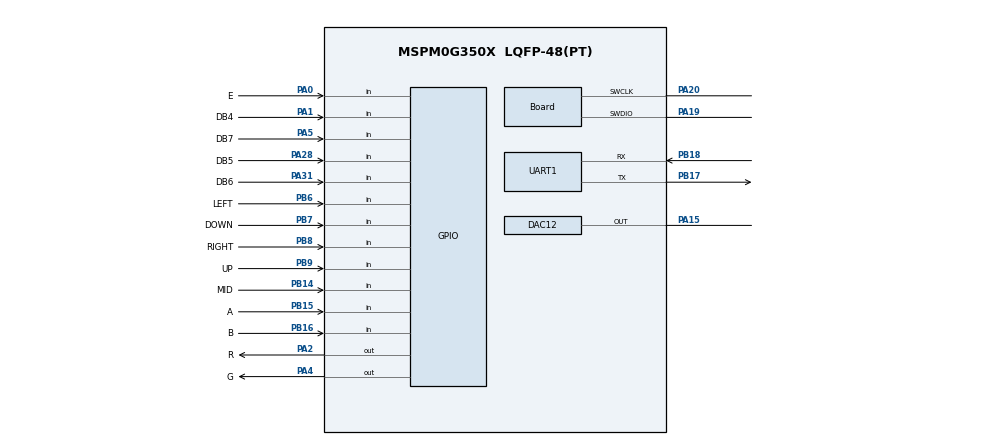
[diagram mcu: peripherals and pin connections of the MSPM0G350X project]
/**
 * @cliArgs --device "MSPM0G350X" --part "Default" --package "LQFP-48(PT)" --product "mspm0_sdk@2.04.00.06"
 * @versions {"tool":"1.23.1+4034"}
 */

/**
 * Import the modules used in this configuration.
 */
const ADC12   = scripting.addModule("/ti/driverlib/ADC12", {}, false);
const ADC121  = ADC12.addInstance();
const DAC12   = scripting.addModule("/ti/driverlib/DAC12");
const GPIO    = scripting.addModule("/ti/driverlib/GPIO", {}, false);
const GPIO1   = GPIO.addInstance();
const GPIO2   = GPIO.addInstance();
const GPIO3   = GPIO.addInstance();
const GPIO4   = GPIO.addInstance();
const SYSCTL  = scripting.addModule("/ti/driverlib/SYSCTL");
const SYSTICK = scripting.addModule("/ti/driverlib/SYSTICK");
const UART    = scripting.addModule("/ti/driverlib/UART", {}, false);
const UART1   = UART.addInstance();
const UART2   = UART.addInstance();

/**
 * Write custom configuration values to the imported modules.
 */
const gate8  = system.clockTree["MFPCLKGATE"];
gate8.enable = true;

const pinFunction3     = system.clockTree["HFCLKEXT"];
pinFunction3.inputFreq = 40;

ADC121.$name                 = "ADC12_0";
ADC121.sampClkDiv            = "DL_ADC12_CLOCK_DIVIDE_8";
ADC121.samplingOperationMode = "sequence";
ADC121.endAdd                = 1;
ADC121.enabledInterrupts     = ["DL_ADC12_INTERRUPT_MEM1_RESULT_LOADED"];
ADC121.interruptPriority     = "3";
ADC121.sampleTime0           = "40 us";
ADC121.adcPin0Config.$name   = "ti_driverlib_gpio_GPIOPinGeneric3";

const Board                       = scripting.addModule("/ti/driverlib/Board", {}, false);
Board.peripheral.$assign          = "DEBUGSS";
Board.peripheral.swclkPin.$assign = "PA20";
Board.peripheral.swdioPin.$assign = "PA19";

DAC12.dacOutputPinEn            = true;
DAC12.dacAmplifier              = "ON";
DAC12.peripheral.$assign        = "DAC0";
DAC12.peripheral.OutPin.$assign = "PA15";
DAC12.OutPinConfig.$name        = "ti_driverlib_gpio_GPIOPinGeneric0";

GPIO1.$name                          = "GPIO_LEDS";
GPIO1.associatedPins.create(3);
GPIO1.associatedPins[0].assignedPort = "PORTA";
GPIO1.associatedPins[0].assignedPin  = "3";
GPIO1.associatedPins[0].$name        = "LED";
GPIO1.associatedPins[1].$name        = "G";
GPIO1.associatedPins[1].assignedPort = "PORTA";
GPIO1.associatedPins[1].assignedPin  = "4";
GPIO1.associatedPins[1].pin.$assign  = "PA4";
GPIO1.associatedPins[2].$name        = "R";
GPIO1.associatedPins[2].assignedPort = "PORTA";
GPIO1.associatedPins[2].assignedPin  = "2";
GPIO1.associatedPins[2].pin.$assign  = "PA2";

GPIO2.$name                               = "GPIO_BTN";
GPIO2.associatedPins.create(5);
GPIO2.associatedPins[0].direction         = "INPUT";
GPIO2.associatedPins[0].assignedPort      = "PORTB";
GPIO2.associatedPins[0].assignedPin       = "6";
GPIO2.associatedPins[0].interruptPriority = "1";
GPIO2.associatedPins[0].$name             = "LEFT";
GPIO2.associatedPins[0].internalResistor  = "PULL_UP";
GPIO2.associatedPins[0].pin.$assign       = "PB6";
GPIO2.associatedPins[1].direction         = "INPUT";
GPIO2.associatedPins[1].assignedPort      = "PORTB";
GPIO2.associatedPins[1].internalResistor  = "PULL_UP";
GPIO2.associatedPins[1].assignedPin       = "7";
GPIO2.associatedPins[1].$name             = "DOWN";
GPIO2.associatedPins[1].pin.$assign       = "PB7";
GPIO2.associatedPins[2].$name             = "RIGHT";
GPIO2.associatedPins[2].direction         = "INPUT";
GPIO2.associatedPins[2].internalResistor  = "PULL_UP";
GPIO2.associatedPins[2].assignedPort      = "PORTB";
GPIO2.associatedPins[2].assignedPin       = "8";
GPIO2.associatedPins[2].pin.$assign       = "PB8";
GPIO2.associatedPins[3].$name             = "UP";
GPIO2.associatedPins[3].direction         = "INPUT";
GPIO2.associatedPins[3].assignedPort      = "PORTB";
GPIO2.associatedPins[3].assignedPin       = "9";
GPIO2.associatedPins[3].internalResistor  = "PULL_UP";
GPIO2.associatedPins[3].pin.$assign       = "PB9";
GPIO2.associatedPins[4].$name             = "MID";
GPIO2.associatedPins[4].direction         = "INPUT";
GPIO2.associatedPins[4].assignedPort      = "PORTB";
GPIO2.associatedPins[4].assignedPin       = "14";
GPIO2.associatedPins[4].internalResistor  = "PULL_UP";
GPIO2.associatedPins[4].pin.$assign       = "PB14";

GPIO3.$name                         = "GPIO_ENCODER";
GPIO3.port                          = "PORTB";
GPIO3.associatedPins.create(2);
GPIO3.associatedPins[0].$name       = "A";
GPIO3.associatedPins[0].direction   = "INPUT";
GPIO3.associatedPins[0].assignedPin = "15";
GPIO3.associatedPins[0].interruptEn = true;
GPIO3.associatedPins[0].polarity    = "RISE";
GPIO3.associatedPins[0].pin.$assign = "PB15";
GPIO3.associatedPins[1].$name       = "B";
GPIO3.associatedPins[1].direction   = "INPUT";
GPIO3.associatedPins[1].assignedPin = "16";
GPIO3.associatedPins[1].interruptEn = true;
GPIO3.associatedPins[1].polarity    = "RISE";
GPIO3.associatedPins[1].pin.$assign = "PB16";

GPIO4.$name                               = "GPIO_FREQ_DECODER";
GPIO4.port                                = "PORTA";
GPIO4.associatedPins.create(5);
GPIO4.associatedPins[0].direction         = "INPUT";
GPIO4.associatedPins[0].$name             = "E";
GPIO4.associatedPins[0].interruptEn       = true;
GPIO4.associatedPins[0].interruptPriority = "2";
GPIO4.associatedPins[0].polarity          = "RISE";
GPIO4.associatedPins[0].assignedPin       = "0";
GPIO4.associatedPins[0].pin.$assign       = "PA0";
GPIO4.associatedPins[1].$name             = "DB4";
GPIO4.associatedPins[1].direction         = "INPUT";
GPIO4.associatedPins[1].assignedPin       = "1";
GPIO4.associatedPins[1].pin.$assign       = "PA1";
GPIO4.associatedPins[2].$name             = "DB5";
GPIO4.associatedPins[2].direction         = "INPUT";
GPIO4.associatedPins[2].assignedPin       = "28";
GPIO4.associatedPins[2].pin.$assign       = "PA28";
GPIO4.associatedPins[3].direction         = "INPUT";
GPIO4.associatedPins[3].$name             = "DB6";
GPIO4.associatedPins[3].assignedPin       = "31";
GPIO4.associatedPins[3].pin.$assign       = "PA31";
GPIO4.associatedPins[4].$name             = "DB7";
GPIO4.associatedPins[4].direction         = "INPUT";
GPIO4.associatedPins[4].assignedPin       = "5";
GPIO4.associatedPins[4].pin.$assign       = "PA5";

SYSCTL.forceDefaultClkConfig = true;
SYSCTL.MFPCLKEn              = true;
SYSCTL.clockTreeEn           = true;

SYSTICK.interruptEnable   = true;
SYSTICK.interruptPriority = "0";
SYSTICK.systickEnable     = true;
SYSTICK.periodEnable      = true;
SYSTICK.period            = 32000;

UART1.$name                    = "UART_0";
UART1.targetBaudRate           = 115200;
UART1.enabledInterrupts        = ["RX"];
UART1.peripheral.$assign       = "UART2";
UART1.peripheral.rxPin.$assign = "PB18";
UART1.peripheral.txPin.$assign = "PB17";
UART1.txPinConfig.$name        = "ti_driverlib_gpio_GPIOPinGeneric1";
UART1.rxPinConfig.$name        = "ti_driverlib_gpio_GPIOPinGeneric2";

UART2.$name             = "UART_1";
UART2.targetBaudRate    = 115200;
UART2.txPinConfig.$name = "ti_driverlib_gpio_GPIOPinGeneric4";
UART2.rxPinConfig.$name = "ti_driverlib_gpio_GPIOPinGeneric5";

const ProjectConfig              = scripting.addModule("/ti/project_config/ProjectConfig", {}, false);
ProjectConfig.migrationCondition = true;

/**
 * Pinmux solution for unlocked pins/peripherals. This ensures that minor changes to the automatic solver in a future
 * version of the tool will not impact the pinmux you originally saw.  These lines can be completely deleted in order to
 * re-solve from scratch.
 */
ADC121.peripheral.$suggestSolution           = "ADC0";
ADC121.peripheral.adcPin0.$suggestSolution   = "PA27";
GPIO1.associatedPins[0].pin.$suggestSolution = "PA3";
UART2.peripheral.$suggestSolution            = "UART0";
UART2.peripheral.rxPin.$suggestSolution      = "PA11";
UART2.peripheral.txPin.$suggestSolution      = "PA10";
